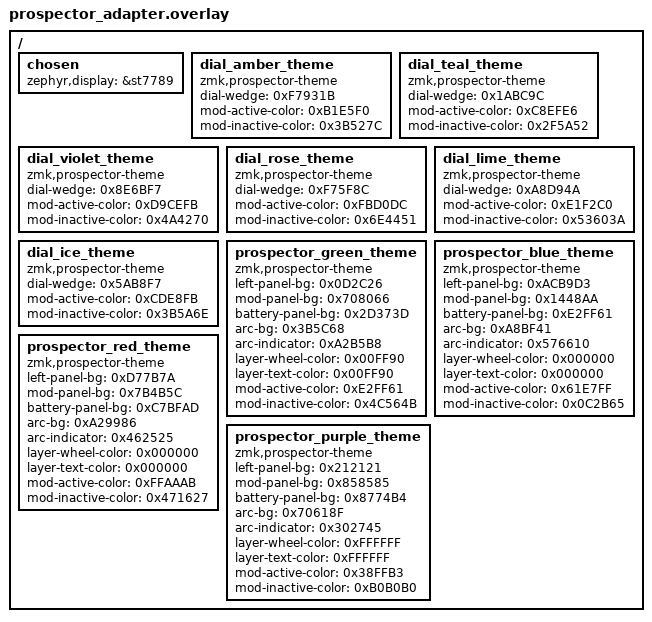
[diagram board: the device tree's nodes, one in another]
/ {
   chosen {
      zephyr,display = &st7789;
   };

   /*
    * Dial layout themes. Each sets only the timer family plus its accent;
    * everything else falls back to the defaults in the binding. Select one
    * with a chosen node in your keymap or shield overlay:
    *
    *   chosen { zmk,prospector-theme = &dial_teal_theme; };
    *
    * dial_amber_theme is the fallback when nothing is chosen.
    */

   dial_amber_theme: dial_amber_theme {
      compatible = "zmk,prospector-theme";
      dial-wedge = <0xF7931B>;
      mod-active-color = <0xB1E5F0>;
      mod-inactive-color = <0x3B527C>;
   };

   dial_teal_theme: dial_teal_theme {
      compatible = "zmk,prospector-theme";
      dial-wedge = <0x1ABC9C>;
      mod-active-color = <0xC8EFE6>;
      mod-inactive-color = <0x2F5A52>;
   };

   dial_violet_theme: dial_violet_theme {
      compatible = "zmk,prospector-theme";
      dial-wedge = <0x8E6BF7>;
      mod-active-color = <0xD9CEFB>;
      mod-inactive-color = <0x4A4270>;
   };

   dial_rose_theme: dial_rose_theme {
      compatible = "zmk,prospector-theme";
      dial-wedge = <0xF75F8C>;
      mod-active-color = <0xFBD0DC>;
      mod-inactive-color = <0x6E4451>;
   };

   dial_lime_theme: dial_lime_theme {
      compatible = "zmk,prospector-theme";
      dial-wedge = <0xA8D94A>;
      mod-active-color = <0xE1F2C0>;
      mod-inactive-color = <0x53603A>;
   };

   dial_ice_theme: dial_ice_theme {
      compatible = "zmk,prospector-theme";
      dial-wedge = <0x5AB8F7>;
      mod-active-color = <0xCDE8FB>;
      mod-inactive-color = <0x3B5A6E>;
   };

   prospector_green_theme: prospector_green_theme {
      compatible = "zmk,prospector-theme";
      left-panel-bg = <0x0D2C26>;
      mod-panel-bg = <0x708066>;
      battery-panel-bg = <0x2D373D>;
      arc-bg = <0x3B5C68>;
      arc-indicator = <0xA2B5B8>;
      layer-wheel-color = <0x00FF90>;
      layer-text-color = <0x00FF90>;
      mod-active-color = <0xE2FF61>;
      mod-inactive-color = <0x4C564B>;
   };

   prospector_blue_theme: prospector_blue_theme {
      compatible = "zmk,prospector-theme";
      left-panel-bg = <0xACB9D3>;
      mod-panel-bg = <0x1448AA>;
      battery-panel-bg = <0xE2FF61>;
      arc-bg = <0xA8BF41>;
      arc-indicator = <0x576610>;
      layer-wheel-color = <0x000000>;
      layer-text-color = <0x000000>;
      mod-active-color = <0x61E7FF>;
      mod-inactive-color = <0x0C2B65>;
   };

   prospector_red_theme: prospector_red_theme {
      compatible = "zmk,prospector-theme";
      left-panel-bg = <0xD77B7A>;
      mod-panel-bg = <0x7B4B5C>;
      battery-panel-bg = <0xC7BFAD>;
      arc-bg = <0xA29986>;
      arc-indicator = <0x462525>;
      layer-wheel-color = <0x000000>;
      layer-text-color = <0x000000>;
      mod-active-color = <0xFFAAAB>;
      mod-inactive-color = <0x471627>;
   };

   prospector_purple_theme: prospector_purple_theme {
      compatible = "zmk,prospector-theme";
      left-panel-bg = <0x212121>;
      mod-panel-bg = <0x858585>;
      battery-panel-bg = <0x8774B4>;
      arc-bg = <0x70618F>;
      arc-indicator = <0x302745>;
      layer-wheel-color = <0xFFFFFF>;
      layer-text-color = <0xFFFFFF>;
      mod-active-color = <0x38FFB3>;
      mod-inactive-color = <0xB0B0B0>;
   };
};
